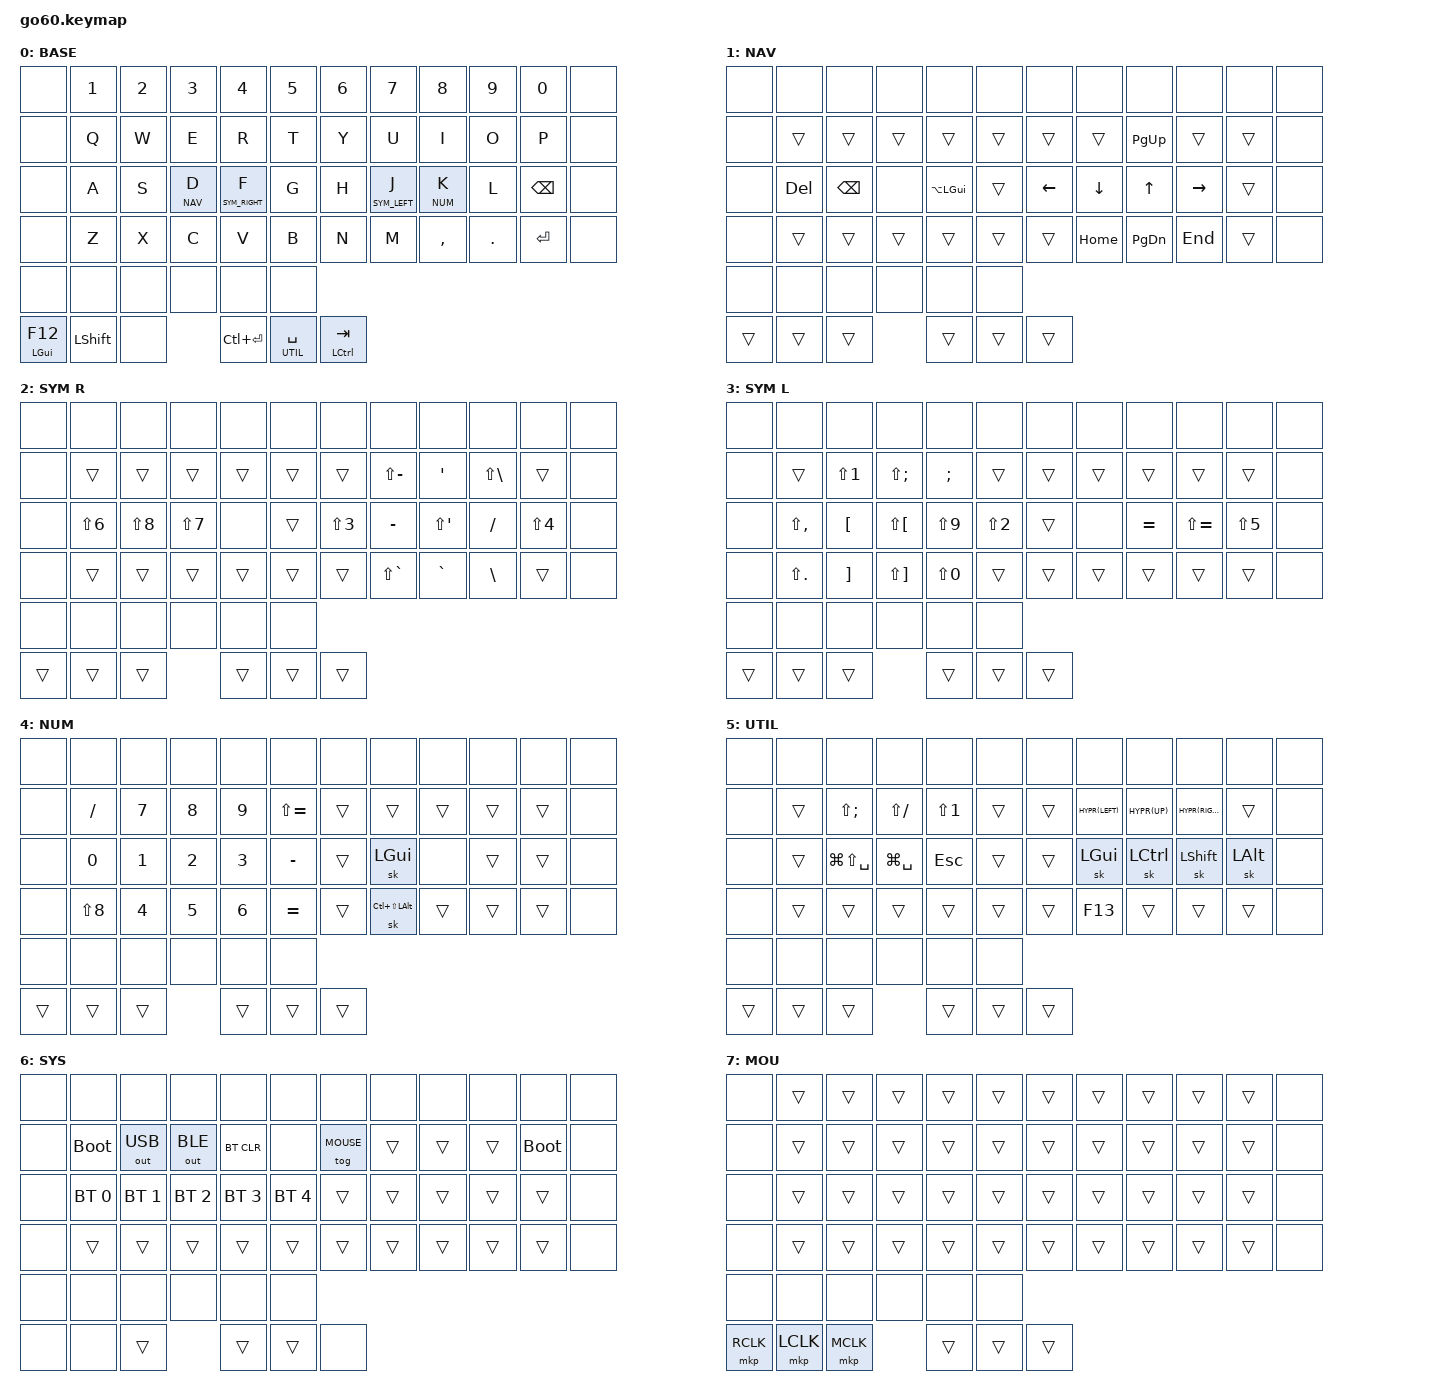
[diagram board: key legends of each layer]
/*
 * Toucan-inspired 34-key layout for the MoErgo Go60.
 *
 * SPDX-License-Identifier: MIT
 */

#include <behaviors.dtsi>

#include <dt-bindings/zmk/bt.h>
#include <dt-bindings/zmk/keys.h>
#include <dt-bindings/zmk/outputs.h>
#include <dt-bindings/zmk/pointing.h>

#include <input/processors.dtsi>
#include <zephyr/dt-bindings/input/input-event-codes.h>

#define BASE 0
#define NAV 1
#define SYM_RIGHT 2
#define SYM_LEFT 3
#define NUM 4
#define UTIL 5
#define SYS 6
#define MOUSE 7

#define QUICK_TAP_MS 175

#define _HYPR(kc) &kp LC(LS(LA(LG(kc))))
#define _MEH(kc) &kp LC(LS(LA(kc)))
#define _RAYCAST &kp LG(SPACE)
#define _1PASS &kp LG(LS(SPACE))

/* Go60 physical positions used by combos. */
#define GO60_L_C3R3 27
#define GO60_L_C2R3 28
#define GO60_L_C4R4 38
#define GO60_L_C3R4 39
#define GO60_L_C2R4 40
#define GO60_R_C2R4 43
#define GO60_R_C3R4 44
#define GO60_R_C4R4 45
#define GO60_R_T3 57
#define GO60_R_T2 58

&mt {
    flavor = "balanced";
    tapping-term-ms = <280>;
    quick-tap-ms = <QUICK_TAP_MS>;
    require-prior-idle-ms = <QUICK_TAP_MS>;
};

&lt {
    flavor = "balanced";
    tapping-term-ms = <200>;
    quick-tap-ms = <QUICK_TAP_MS>;
};

&sk {
    release-after-ms = <900>;
    quick-release;
    ignore-modifiers;
};

/ {
    input_processors {
        zip_click_to_right_click_mapper: zip_click_to_right_click_mapper {
            compatible = "zmk,input-processor-code-mapper";
            #input-processor-cells = <0>;
            type = <INPUT_EV_KEY>;
            map = <INPUT_BTN_0 INPUT_BTN_1>;
        };
    };

    behaviors {
        qt: quick_tap {
            compatible = "zmk,behavior-hold-tap";
            label = "QUICK_TAP";
            #binding-cells = <2>;
            flavor = "hold-preferred";
            tapping-term-ms = <200>;
            quick-tap-ms = <200>;
            bindings = <&kp>, <&kp>;
        };
    };

    combos {
        compatible = "zmk,combos";

        combo_sys {
            timeout-ms = <200>;
            key-positions = <GO60_R_T3 GO60_R_T2>;
            bindings = <&mo SYS>;
        };

        combo_esc {
            timeout-ms = <50>;
            key-positions = <GO60_L_C3R3 GO60_L_C2R3>;
            bindings = <&kp ESC>;
        };

        combo_hypr_l {
            timeout-ms = <50>;
            key-positions = <GO60_L_C4R4 GO60_L_C3R4>;
            bindings = <&kp LG(LC(LS(LALT)))>;
        };

        combo_meh_l {
            timeout-ms = <50>;
            key-positions = <GO60_L_C3R4 GO60_L_C2R4>;
            bindings = <&kp LC(LS(LALT))>;
        };

        combo_meh_r {
            timeout-ms = <50>;
            key-positions = <GO60_R_C2R4 GO60_R_C3R4>;
            bindings = <&kp LC(LS(LALT))>;
        };

        combo_hypr_r {
            timeout-ms = <50>;
            key-positions = <GO60_R_C3R4 GO60_R_C4R4>;
            bindings = <&kp LG(LC(LS(LALT)))>;
        };
    };

    keymap {
        compatible = "zmk,keymap";

        base {
            display-name = "BASE";
            bindings = <
                &none  &kp N1  &kp N2  &kp N3  &kp N4  &kp N5    &kp N6  &kp N7  &kp N8  &kp N9  &kp N0  &none
                &none  &kp Q  &kp W  &kp E  &kp R  &kp T    &kp Y  &kp U  &kp I  &kp O  &kp P  &none
                &none  &kp A  &kp S  &lt NAV D  &lt SYM_RIGHT F  &kp G    &kp H  &lt SYM_LEFT J  &lt NUM K  &kp L  &kp BSPC  &none
                &none  &kp Z  &kp X  &kp C  &kp V  &kp B    &kp N  &kp M  &kp COMMA  &kp DOT  &kp ENTER  &none
                &none  &none  &none    &none  &none  &none
                &mt LGUI F12  &kp LSHIFT  &none    &kp LC(ENTER)  &lt UTIL SPACE  &mt LCTRL TAB
            >;
        };

        nav {
            display-name = "NAV";
            bindings = <
                &none  &none  &none  &none  &none  &none    &none  &none  &none  &none  &none  &none
                &none  &trans  &trans  &trans  &trans  &trans    &trans  &trans  &kp PG_UP  &trans  &trans  &none
                &none  &kp DEL  &kp BSPC  &none  &kp LA(LGUI)  &trans    &kp LEFT  &kp DOWN  &kp UP  &kp RIGHT  &trans  &none
                &none  &trans  &trans  &trans  &trans  &trans    &trans  &kp HOME  &kp PG_DN  &kp END  &trans  &none
                &none  &none  &none    &none  &none  &none
                &trans  &trans  &trans    &trans  &trans  &trans
            >;
        };

        sym_right {
            display-name = "SYM R";
            bindings = <
                &none  &none  &none  &none  &none  &none    &none  &none  &none  &none  &none  &none
                &none  &trans  &trans  &trans  &trans  &trans    &trans  &kp LS(MINUS)  &kp SQT  &kp LS(BSLH)  &trans  &none
                &none  &kp LS(N6)  &kp LS(N8)  &kp LS(N7)  &none  &trans    &kp LS(N3)  &kp MINUS  &kp LS(SINGLE_QUOTE)  &kp FSLH  &kp LS(N4)  &none
                &none  &trans  &trans  &trans  &trans  &trans    &trans  &kp LS(GRAVE)  &kp GRAVE  &kp BSLH  &trans  &none
                &none  &none  &none    &none  &none  &none
                &trans  &trans  &trans    &trans  &trans  &trans
            >;
        };

        sym_left {
            display-name = "SYM L";
            bindings = <
                &none  &none  &none  &none  &none  &none    &none  &none  &none  &none  &none  &none
                &none  &trans  &kp LS(N1)  &kp LS(SEMI)  &kp SEMI  &trans    &trans  &trans  &trans  &trans  &trans  &none
                &none  &kp LS(COMMA)  &kp LBKT  &kp LS(LBKT)  &kp LS(N9)  &kp LS(N2)    &trans  &none  &kp EQUAL  &kp LS(EQUAL)  &kp LS(N5)  &none
                &none  &kp LS(DOT)  &kp RBKT  &kp LS(RBKT)  &kp LS(N0)  &trans    &trans  &trans  &trans  &trans  &trans  &none
                &none  &none  &none    &none  &none  &none
                &trans  &trans  &trans    &trans  &trans  &trans
            >;
        };

        num {
            display-name = "NUM";
            bindings = <
                &none  &none  &none  &none  &none  &none    &none  &none  &none  &none  &none  &none
                &none  &kp FSLH  &kp N7  &kp N8  &kp N9  &kp LS(EQUAL)    &trans  &trans  &trans  &trans  &trans  &none
                &none  &kp N0  &kp N1  &kp N2  &kp N3  &kp MINUS    &trans  &sk LGUI  &none  &trans  &trans  &none
                &none  &kp LS(N8)  &kp N4  &kp N5  &kp N6  &kp EQUAL    &trans  &sk LC(LS(LALT))  &trans  &trans  &trans  &none
                &none  &none  &none    &none  &none  &none
                &trans  &trans  &trans    &trans  &trans  &trans
            >;
        };

        util {
            display-name = "UTIL";
            bindings = <
                &none  &none  &none  &none  &none  &none    &none  &none  &none  &none  &none  &none
                &none  &trans  &kp LS(SEMI)  &kp LS(FSLH)  &kp LS(N1)  &trans    &trans  _HYPR(LEFT)  _HYPR(UP)  _HYPR(RIGHT)  &trans  &none
                &none  &trans  _1PASS  _RAYCAST  &kp ESC  &trans    &trans  &sk LGUI  &sk LCTRL  &sk LSHIFT  &sk LALT  &none
                &none  &trans  &trans  &trans  &trans  &trans    &trans  &kp F13  &trans  &trans  &trans  &none
                &none  &none  &none    &none  &none  &none
                &trans  &trans  &trans    &trans  &trans  &trans
            >;
        };

        sys {
            display-name = "SYS";
            bindings = <
                &none  &none  &none  &none  &none  &none    &none  &none  &none  &none  &none  &none
                &none  &bootloader  &out OUT_USB  &out OUT_BLE  &bt BT_CLR  &none    &tog MOUSE  &trans  &trans  &trans  &bootloader  &none
                &none  &bt BT_SEL 0  &bt BT_SEL 1  &bt BT_SEL 2  &bt BT_SEL 3  &bt BT_SEL 4    &trans  &trans  &trans  &trans  &trans  &none
                &none  &trans  &trans  &trans  &trans  &trans    &trans  &trans  &trans  &trans  &trans  &none
                &none  &none  &none    &none  &none  &none
                &none  &none  &trans    &trans  &trans  &none
            >;
        };

        mouse {
            display-name = "MOU";
            bindings = <
                &none  &trans  &trans  &trans  &trans  &trans    &trans  &trans  &trans  &trans  &trans  &none
                &none  &trans  &trans  &trans  &trans  &trans    &trans  &trans  &trans  &trans  &trans  &none
                &none  &trans  &trans  &trans  &trans  &trans    &trans  &trans  &trans  &trans  &trans  &none
                &none  &trans  &trans  &trans  &trans  &trans    &trans  &trans  &trans  &trans  &trans  &none
                &none  &none  &none    &none  &none  &none
                &mkp RCLK  &mkp LCLK  &mkp MCLK    &trans  &trans  &trans
            >;
        };
    };
};

/* Dual-Cirque configuration, with the left pad scaled before scroll mapping. */
&cirque_rh_listener {
    input-processors = <&zip_xy_scaler 3 1>;
    layer_2 {
        layers = <2>;
        input-processors = <&zip_xy_scaler 9 1>;
    };
};

&cirque_lh_listener {
    input-processors = <&zip_xy_scaler 1 8>, <&zip_xy_to_scroll_mapper>, <&zip_click_to_right_click_mapper>;
    layer_4 {
        layers = <4>;
        input-processors = <&zip_xy_scaler 3 1>;
    };
};
